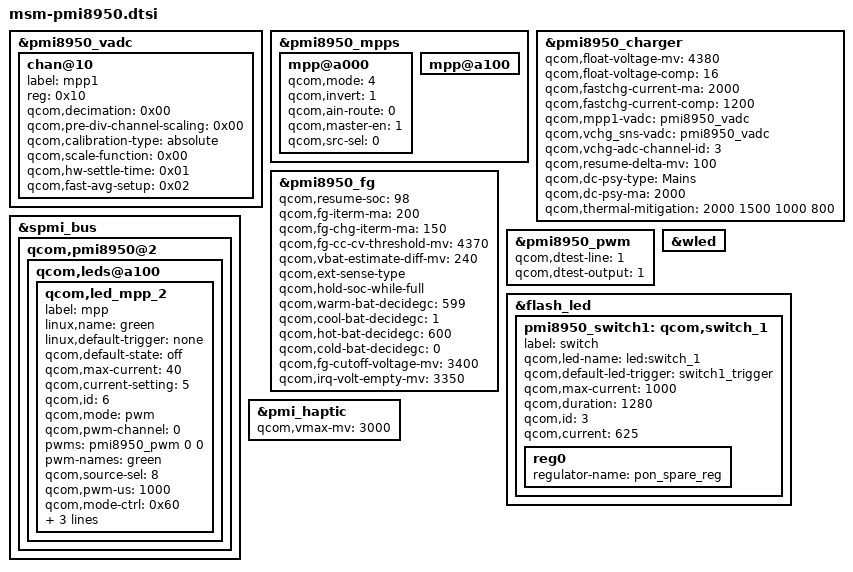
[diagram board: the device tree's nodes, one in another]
/*
 * Copyright (c) 2015-2018, The Linux Foundation. All rights reserved.
 *
 * This program is free software; you can redistribute it and/or modify
 * it under the terms of the GNU General Public License version 2 and
 * only version 2 as published by the Free Software Foundation.
 *
 * This program is distributed in the hope that it will be useful,
 * but WITHOUT ANY WARRANTY; without even the implied warranty of
 * MERCHANTABILITY or FITNESS FOR A PARTICULAR PURPOSE.  See the
 * GNU General Public License for more details.
 */

&pmi8950_vadc {
	chan@10 {
		label = "mpp1";
		reg = <0x10>;
		qcom,decimation = <0x00>;
		qcom,pre-div-channel-scaling = <0x00>;
		qcom,calibration-type = "absolute";
		qcom,scale-function = <0x00>;
		qcom,hw-settle-time = <0x01>;
		qcom,fast-avg-setup = <0x02>;
	};
};

&pmi8950_mpps {
	mpp@a000 {
		/delete-property/ status;

		qcom,mode = <4>;
		qcom,invert = <1>;
		qcom,ain-route = <0>;
		qcom,master-en = <1>;
		qcom,src-sel = <0>;
	};

	mpp@a100 {
		/delete-property/ status;
	};
};

&pmi8950_charger {
	/delete-property/ qcom,parallel-usb-min-current-ma;
	/delete-property/ qcom,parallel-usb-9v-min-current-ma;
	/delete-property/ qcom,parallel-allowed-lowering-ma;

	qcom,float-voltage-mv = <4380>;
	qcom,float-voltage-comp = <16>;    /*4.08V*/
	qcom,fastchg-current-ma = <2000>;
	qcom,fastchg-current-comp = <1200>; /*1.2A*/
	qcom,mpp1-vadc = <&pmi8950_vadc>;
	qcom,vchg_sns-vadc = <&pmi8950_vadc>;
	qcom,vchg-adc-channel-id = <3>;		
	qcom,resume-delta-mv = <100>;	//<200>;
	qcom,dc-psy-type = "Mains";
	qcom,dc-psy-ma = <2000>;
	qcom,thermal-mitigation = <2000 1500 1000 800>; //<1500 700 600 0>;
};

&pmi8950_fg {
	qcom,resume-soc = <98>;
	qcom,fg-iterm-ma = <200>; //<150>
	qcom,fg-chg-iterm-ma = <150>; //<100>
	qcom,fg-cc-cv-threshold-mv = <4370>;
	qcom,vbat-estimate-diff-mv = <240>;
	qcom,ext-sense-type;
	qcom,hold-soc-while-full;
	qcom,warm-bat-decidegc = <599>;
	qcom,cool-bat-decidegc = <1>;
	qcom,hot-bat-decidegc = <600>;
	qcom,cold-bat-decidegc = <0>;
	qcom,fg-cutoff-voltage-mv = <3400>; //<3500>
	qcom,irq-volt-empty-mv = <3350>;
};

&spmi_bus {
	qcom,pmi8950@2 {
		qcom,leds@a100 {
			qcom,led_mpp_2 {
				label = "mpp";
				linux,name = "green";
				linux,default-trigger = "none";
				qcom,default-state = "off";
				qcom,max-current = <40>;
				qcom,current-setting = <5>;
				qcom,id = <6>;

				qcom,mode = "pwm";
				qcom,pwm-channel = <0>;
				pwms = <&pmi8950_pwm 0 0>;
				pwm-names="green";
				qcom,source-sel = <8>;
				qcom,pwm-us = <1000>;
				qcom,mode-ctrl = <0x60>;
				qcom,pwm-use-blink;
				qcom,pwm-blink-onms = <200>;
				qcom,pwm-blink-offms = <1800>;
			};
		};
	};
};

&pmi8950_pwm {
	status = "okay";
	qcom,dtest-line = <1>;
	qcom,dtest-output = <1>;
};

&wled {
	/delete-property/ qcom,en-ext-pfet-sc-pro;
};

&flash_led {
	pmi8950_switch1: qcom,switch_1 {
		label = "switch";
		qcom,led-name = "led:switch_1";
		qcom,default-led-trigger =
				"switch1_trigger";
		qcom,max-current = <1000>;
		qcom,duration = <1280>;
		qcom,id = <3>;
		qcom,current = <625>;
		reg0 {
			regulator-name = "pon_spare_reg";
		};
	};
};

&pmi_haptic {
	/delete-property/ interrupts;
	/delete-property/ interrupt-names;
	/delete-property/ vcc_pon-supply;
	/delete-property/ qcom,wave-shape;
	/delete-property/ qcom,sc-deb-cycles;
	/delete-property/ qcom,int-pwm-freq-khz;
	/delete-property/ qcom,en-brake;
	/delete-property/ qcom,brake-pattern;
	/delete-property/ qcom,use-play-irq;
	/delete-property/ qcom,use-sc-irq;
	/delete-property/ qcom,wave-samples;
	/delete-property/ qcom,wave-rep-cnt;
	/delete-property/ qcom,wave-samp-rep-cnt;
	/delete-property/ qcom,lra-auto-res-mode;
	/delete-property/ qcom,lra-high-z;
	/delete-property/ qcom,lra-res-cal-period;
	/delete-property/ qcom,correct-lra-drive-freq;
	/delete-property/ qcom,misc-trim-error-rc19p2-clk-reg-present;

	/* status = "ok"; */
	/* qcom,actuator-type = "erm"; */
	qcom,vmax-mv = <3000>;
	/* qcom,wave-play-rate-us = <5263>; */
};
